# ESP32S31_PLATFORM_RADIO_DEPENDENCIES register map
Vendor: Espressif; Series: ESP32-S31; File version: 1.0
Validator catalog for platform-owned registers reached by the ESP32-S31 radio call graph. The definitions mirror the pinned official platform PAC SVD and do not create a second runtime owner; production code uses the generated esp32s31 PAC through the esp-hal integration layer.
Registers are 32-bit, read-write, reset 0x0 unless marked. A register's access mark holds for its fields unless they carry their own. Offsets are from the block's base; lines under a group give offsets from that group; [hi:lo] are bit positions; {n}, {i} and the like mark numbered series; 'fields as' and 'values as' point back to an identical list; <NAME> marks a mode.

## Memory map
0x2010F000 MODEM_LPCON — SOURCE[ESP32S31_PAC_D0FB94E,S31_MODEM_LPCON_STRUCT]. Remaining platform-owned modem low-power configuration registers from the pinned ESP32-S31 PAC; the shared clock registers and TICK_CONF are carved into canonical route-owned models.
0x20704000 PMU — SOURCE[ESP32S31_PAC_D0FB94E,BLOB_LIBPHY_PHY_OPEN_I2C_XPD_NEW,ROM_REV0_PHY_OPEN_FE_BB_CLK]. Platform-owned power-management registers reached by radio initialization.
0x20715000 EFUSE — SOURCE[ESP32S31_PAC_D0FB94E]. Platform-owned eFuse controller. Only the two exact read-only MAC words reached by the PHY ROM call graph are mirrored here.

## Further device data
openEspRadioProvenance:
  id=ESP32S31_PAC_D0FB94E
  id=S31_MODEM_LPCON_STRUCT
  id=S31_MODEM_SYSCON_STRUCT
  id=ROM_REV0_PHY_I2C
  id=ROM_REV0_PHY_FREQUENCY_CHANNEL
  id=ROM_REV0_PHY_TSENS
  id=BLOB_LIBPHY_PHY_I2C
  id=BLOB_LIBPHY_PHY_BB_INIT
  id=BLOB_LIBPHY_PHY_OPEN_I2C_XPD_NEW
  id=BLOB_LIBPHY_PHY_TSENS_READ_INIT
  id=ROM_REV0_PHY_OPEN_FE_BB_CLK
  id=ROM_REV0_PHY_POWER_DETECTOR

## MODEM_LPCON — SOURCE[ESP32S31_PAC_D0FB94E,S31_MODEM_LPCON_STRUCT]. Remaining platform-owned modem low-power configuration registers from the pinned ESP32-S31 PAC; the shared clock registers and TICK_CONF are carved into canonical route-owned models.
Base 0x2010F000
0x00 TEST_CONF
  [0] CLK_EN
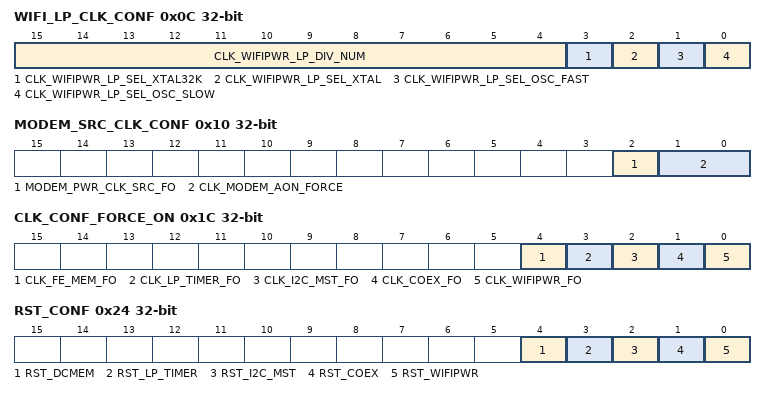
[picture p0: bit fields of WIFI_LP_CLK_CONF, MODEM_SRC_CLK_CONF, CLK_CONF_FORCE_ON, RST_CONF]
0x0C WIFI_LP_CLK_CONF
  [15:4] CLK_WIFIPWR_LP_DIV_NUM, [3] CLK_WIFIPWR_LP_SEL_XTAL32K, [2] CLK_WIFIPWR_LP_SEL_XTAL, [1] CLK_WIFIPWR_LP_SEL_OSC_FAST, [0] CLK_WIFIPWR_LP_SEL_OSC_SLOW
0x10 MODEM_SRC_CLK_CONF
  [2] MODEM_PWR_CLK_SRC_FO, [1:0] CLK_MODEM_AON_FORCE
0x14 MODEM_32K_CLK_CONF
  [1:0] CLK_MODEM_32K_SEL
0x1C CLK_CONF_FORCE_ON
  [4] CLK_FE_MEM_FO, [3] CLK_LP_TIMER_FO, [2] CLK_I2C_MST_FO, [1] CLK_COEX_FO, [0] CLK_WIFIPWR_FO
0x24 RST_CONF
  [4] RST_DCMEM, [3] RST_LP_TIMER, [2] RST_I2C_MST, [1] RST_COEX, [0] RST_WIFIPWR
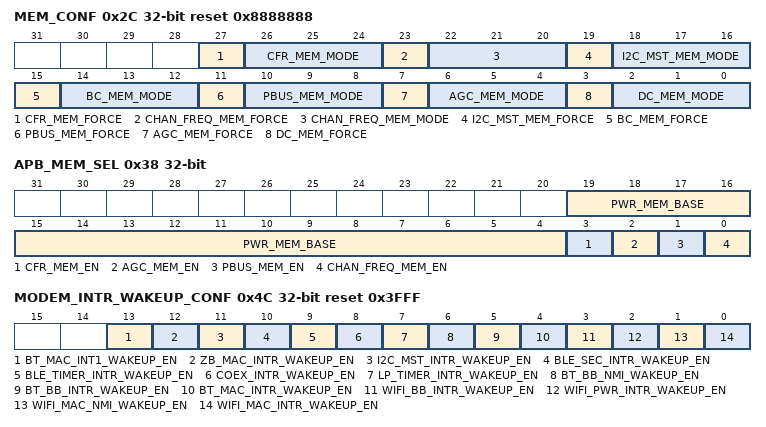
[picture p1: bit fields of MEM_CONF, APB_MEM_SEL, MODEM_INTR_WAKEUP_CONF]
0x2C MEM_CONF reset 0x8888888
  [27] CFR_MEM_FORCE, [26:24] CFR_MEM_MODE, [23] CHAN_FREQ_MEM_FORCE, [22:20] CHAN_FREQ_MEM_MODE, [19] I2C_MST_MEM_FORCE, [18:16] I2C_MST_MEM_MODE, [15] BC_MEM_FORCE, [14:12] BC_MEM_MODE, [11] PBUS_MEM_FORCE, [10:8] PBUS_MEM_MODE, [7] AGC_MEM_FORCE, [6:4] AGC_MEM_MODE, [3] DC_MEM_FORCE, [2:0] DC_MEM_MODE
0x30 MEM_RF1_AUX_CTRL reset 0x2070
  [31:0] MODEM_PWR_RF1_AUX_CTRL
0x34 MEM_RF2_AUX_CTRL
  [31:0] MODEM_PWR_RF2_AUX_CTRL
0x38 APB_MEM_SEL
  [19:4] PWR_MEM_BASE, [3] CFR_MEM_EN, [2] AGC_MEM_EN, [1] PBUS_MEM_EN, [0] CHAN_FREQ_MEM_EN
{0x3C+4i} DCMEM_VALID_{i} (i=0..3)
0x4C MODEM_INTR_WAKEUP_CONF reset 0x3FFF
  [13] BT_MAC_INT1_WAKEUP_EN, [12] ZB_MAC_INTR_WAKEUP_EN, [11] I2C_MST_INTR_WAKEUP_EN, [10] BLE_SEC_INTR_WAKEUP_EN, [9] BLE_TIMER_INTR_WAKEUP_EN, [8] COEX_INTR_WAKEUP_EN, [7] LP_TIMER_INTR_WAKEUP_EN, [6] BT_BB_NMI_WAKEUP_EN, [5] BT_BB_INTR_WAKEUP_EN, [4] BT_MAC_INTR_WAKEUP_EN, [3] WIFI_BB_INTR_WAKEUP_EN, [2] WIFI_PWR_INTR_WAKEUP_EN, [1] WIFI_MAC_NMI_WAKEUP_EN, [0] WIFI_MAC_INTR_WAKEUP_EN
0x50 MODEM_INTR_STATUS
  [13:0] MODEM_INTR_VECTOR
0x54 MEM_CONF2 reset 0x4
  [3:0] PWR_MEM_MODE_SEL
0x58 DATE reset 0x2508150
  [27:0] DATE

## PMU — SOURCE[ESP32S31_PAC_D0FB94E,BLOB_LIBPHY_PHY_OPEN_I2C_XPD_NEW,ROM_REV0_PHY_OPEN_FE_BB_CLK]. Platform-owned power-management registers reached by radio initialization.
Base 0x20704000
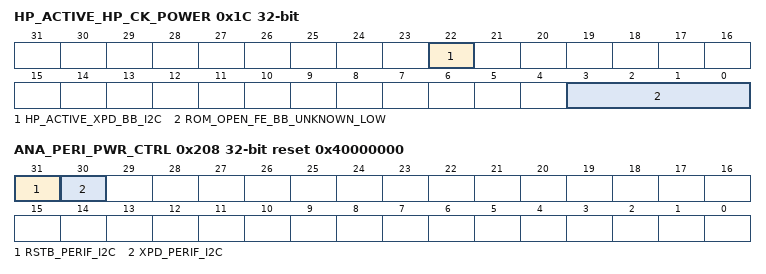
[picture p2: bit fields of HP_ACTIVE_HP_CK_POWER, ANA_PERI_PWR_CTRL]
0x1C HP_ACTIVE_HP_CK_POWER — Active-state high-power clock and analog-I2C power control.
  [22] HP_ACTIVE_XPD_BB_I2C, [3:0] ROM_OPEN_FE_BB_UNKNOWN_LOW
0xF0 IMM_HP_CK_POWER_0 — Immediate high-power clock tie controls used by analog-I2C power-up.
  [28] TIE_HIGH_XPD_BB_I2C
0x184 RF_PWC — RF circuit power control.
  [31:16] XPD_RF_CIRCUIT
0x208 ANA_PERI_PWR_CTRL reset 0x40000000 — Analog peripheral I2C power and reset control.
  [31] RSTB_PERIF_I2C, [30] XPD_PERIF_I2C

## EFUSE — SOURCE[ESP32S31_PAC_D0FB94E]. Platform-owned eFuse controller. Only the two exact read-only MAC words reached by the PHY ROM call graph are mirrored here.
Base 0x20715000
0x50 RD_MAC_SYS0 ro reset not defined — SOURCE[ESP32S31_PAC_D0FB94E]. Exact platform-PAC register and field: low 32 bits of the system MAC address.
  [31:0] MAC_0
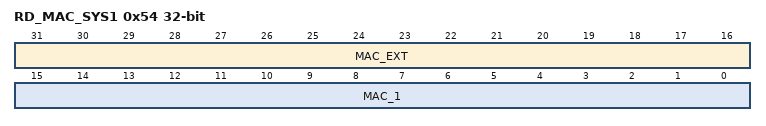
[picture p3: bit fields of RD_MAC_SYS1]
0x54 RD_MAC_SYS1 ro reset not defined — SOURCE[ESP32S31_PAC_D0FB94E]. Exact platform-PAC register and fields: high 16 system-MAC bits and the 16 extended MAC bits.
  [31:16] MAC_EXT, [15:0] MAC_1

## Licence text in the file
MIT OR Apache-2.0
